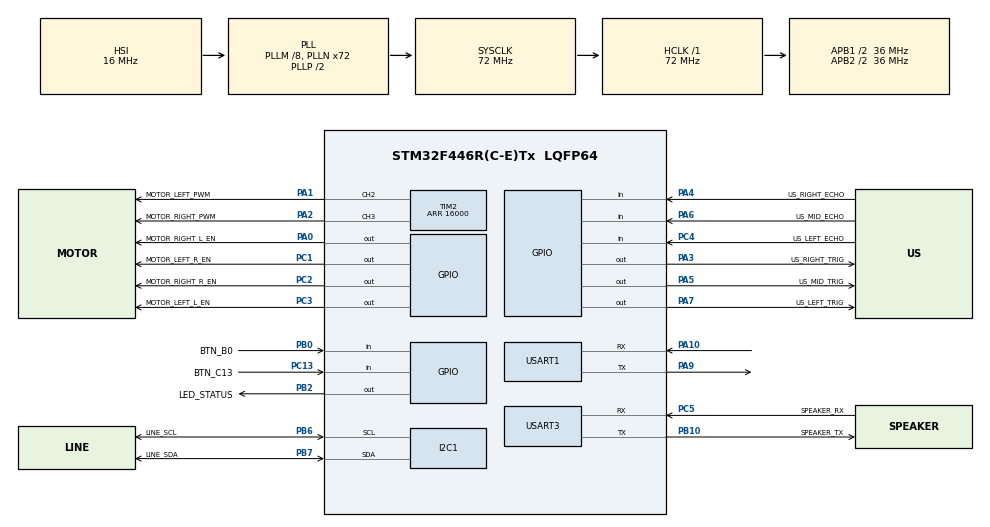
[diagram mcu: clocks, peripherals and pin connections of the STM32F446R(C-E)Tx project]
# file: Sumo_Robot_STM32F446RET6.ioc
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Mcu.Family=STM32F4
Mcu.Name=STM32F446R(C-E)Tx
Mcu.Package=LQFP64
NVIC.PriorityGroup=NVIC_PRIORITYGROUP_4
PA0-WKUP.GPIO_Label=MOTOR_RIGHT_L_EN
PA0-WKUP.Signal=GPIO_Output
PA1.GPIO_Label=MOTOR_LEFT_PWM
PA1.Signal=S_TIM2_CH2
PA10.Mode=Asynchronous
PA10.Signal=USART1_RX
PA2.GPIO_Label=MOTOR_RIGHT_PWM
PA2.Signal=S_TIM2_CH3
PA3.GPIO_Label=US_RIGHT_TRIG
PA3.Signal=GPIO_Output
PA4.GPIO_Label=US_RIGHT_ECHO
PA4.Signal=GPIO_Input
PA5.GPIO_Label=US_MID_TRIG
PA5.Signal=GPIO_Output
PA6.GPIO_Label=US_MID_ECHO
PA6.Signal=GPIO_Input
PA7.GPIO_Label=US_LEFT_TRIG
PA7.Signal=GPIO_Output
PA9.Mode=Asynchronous
PA9.Signal=USART1_TX
PB0.GPIO_Label=BTN_B0
PB0.Signal=GPIO_Input
PB10.GPIO_Label=SPEAKER_TX
PB10.Mode=Asynchronous
PB10.Signal=USART3_TX
PB2.GPIO_Label=LED_STATUS
PB2.Signal=GPIO_Output
PB6.GPIO_Label=LINE_SCL
PB6.Mode=I2C
PB6.Signal=I2C1_SCL
PB7.GPIO_Label=LINE_SDA
PB7.Mode=I2C
PB7.Signal=I2C1_SDA
PC1.GPIO_Label=MOTOR_LEFT_R_EN
PC1.Signal=GPIO_Output
PC13.GPIO_Label=BTN_C13
PC13.Signal=GPIO_Input
PC2.GPIO_Label=MOTOR_RIGHT_R_EN
PC2.Signal=GPIO_Output
PC3.GPIO_Label=MOTOR_LEFT_L_EN
PC3.Signal=GPIO_Output
PC4.GPIO_Label=US_LEFT_ECHO
PC4.Signal=GPIO_Input
PC5.GPIO_Label=SPEAKER_RX
PC5.Mode=Asynchronous
PC5.Signal=USART3_RX
ProjectManager.HeapSize=0x200
ProjectManager.StackSize=0x400
ProjectManager.TargetToolchain=STM32CubeIDE
RCC.AHBFreq_Value=72000000
RCC.APB1CLKDivider=RCC_HCLK_DIV2
RCC.APB1Freq_Value=36000000
RCC.APB1TimFreq_Value=72000000
RCC.APB2CLKDivider=RCC_HCLK_DIV2
RCC.APB2Freq_Value=36000000
RCC.APB2TimFreq_Value=72000000
RCC.CortexFreq_Value=72000000
RCC.HCLKFreq_Value=72000000
RCC.PLLM=8
RCC.PLLN=72
RCC.SYSCLKFreq_VALUE=72000000
RCC.SYSCLKSource=RCC_SYSCLKSOURCE_PLLCLK
RCC.USBFreq_Value=72000000
RCC.VCOOutputFreq_Value=144000000
SH.S_TIM2_CH2.0=TIM2_CH2,PWM Generation2 CH2
SH.S_TIM2_CH3.0=TIM2_CH3,PWM Generation3 CH3
TIM1.Period=0xffff-1
TIM1.Prescaler=101-1
TIM2.Channel-PWM\ Generation2\ CH2=TIM_CHANNEL_2
TIM2.Channel-PWM\ Generation3\ CH3=TIM_CHANNEL_3
TIM2.Period=16000
USART1.VirtualMode=VM_ASYNC
USART3.VirtualMode=VM_ASYNC
VP_TIM1_VS_ClockSourceINT.Mode=Internal
VP_TIM2_VS_ClockSourceINT.Mode=Internal
board=custom

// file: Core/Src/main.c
/* USER CODE BEGIN Header */
/**
  ******************************************************************************
  * @file           : main.c
  * @brief          : Main program body
  ******************************************************************************
  * @attention
  *
  * Copyright (c) 2026 STMicroelectronics.
  * All rights reserved.
  *
  * This software is licensed under terms that can be found in the LICENSE file
  * in the root directory of this software component.
  * If no LICENSE file comes with this software, it is provided AS-IS.
  *
  ******************************************************************************
  */
/* USER CODE END Header */
#include "main.h"
#include "i2c.h"
#include "tim.h"
#include "usart.h"
#include "gpio.h"

/* USER CODE BEGIN Includes */
#include "app/app_main.h"

/* USER CODE END Includes */

void SystemClock_Config(void);

int main(void)
{

  /* MCU Configuration--------------------------------------------------------*/

  /* Reset of all peripherals, Initializes the Flash interface and the Systick. */
  HAL_Init();

  /* Configure the system clock */
  SystemClock_Config();

  /* Initialize all configured peripherals */
  MX_GPIO_Init();
  MX_I2C1_Init();
  MX_TIM1_Init();
  MX_TIM2_Init();
  MX_USART1_UART_Init();
  MX_USART3_UART_Init();
  /* USER CODE BEGIN 2 */
  AppMain_Init();
  /* USER CODE END 2 */

  /* Infinite loop */
  while (1)
  {

    /* USER CODE BEGIN 3 */
    AppMain_Loop();
  }
  /* USER CODE END 3 */
}

void SystemClock_Config(void)
{
  RCC_OscInitTypeDef RCC_OscInitStruct = {0};
  RCC_ClkInitTypeDef RCC_ClkInitStruct = {0};

  /** Configure the main internal regulator output voltage
  */
  __HAL_RCC_PWR_CLK_ENABLE();
  __HAL_PWR_VOLTAGESCALING_CONFIG(PWR_REGULATOR_VOLTAGE_SCALE3);

  /** Initializes the RCC Oscillators according to the specified parameters
  * in the RCC_OscInitTypeDef structure.
  */
  RCC_OscInitStruct.OscillatorType = RCC_OSCILLATORTYPE_HSI;
  RCC_OscInitStruct.HSIState = RCC_HSI_ON;
  RCC_OscInitStruct.HSICalibrationValue = RCC_HSICALIBRATION_DEFAULT;
  RCC_OscInitStruct.PLL.PLLState = RCC_PLL_ON;
  RCC_OscInitStruct.PLL.PLLSource = RCC_PLLSOURCE_HSI;
  RCC_OscInitStruct.PLL.PLLM = 8;
  RCC_OscInitStruct.PLL.PLLN = 72;
  RCC_OscInitStruct.PLL.PLLP = RCC_PLLP_DIV2;
  RCC_OscInitStruct.PLL.PLLQ = 2;
  RCC_OscInitStruct.PLL.PLLR = 2;
  if (HAL_RCC_OscConfig(&RCC_OscInitStruct) != HAL_OK)
  {
    Error_Handler();
  }

  /** Initializes the CPU, AHB and APB buses clocks
  */
  RCC_ClkInitStruct.ClockType = RCC_CLOCKTYPE_HCLK|RCC_CLOCKTYPE_SYSCLK
                              |RCC_CLOCKTYPE_PCLK1|RCC_CLOCKTYPE_PCLK2;
  RCC_ClkInitStruct.SYSCLKSource = RCC_SYSCLKSOURCE_PLLCLK;
  RCC_ClkInitStruct.AHBCLKDivider = RCC_SYSCLK_DIV1;
  RCC_ClkInitStruct.APB1CLKDivider = RCC_HCLK_DIV2;
  RCC_ClkInitStruct.APB2CLKDivider = RCC_HCLK_DIV2;

  if (HAL_RCC_ClockConfig(&RCC_ClkInitStruct, FLASH_LATENCY_2) != HAL_OK)
  {
    Error_Handler();
  }
}

void Error_Handler(void)
{
  __disable_irq();
  while (1)
  {
  }
}
